# ARMv7M register map
Registers are read-write, no defined reset value unless marked. A register's access mark holds for its fields unless they carry their own. Offsets are from the block's base; [hi:lo] are bit positions; {n}, {i} and the like mark numbered series.

## DWT — Data Watchpoint and Trace
Base 0xE0001000
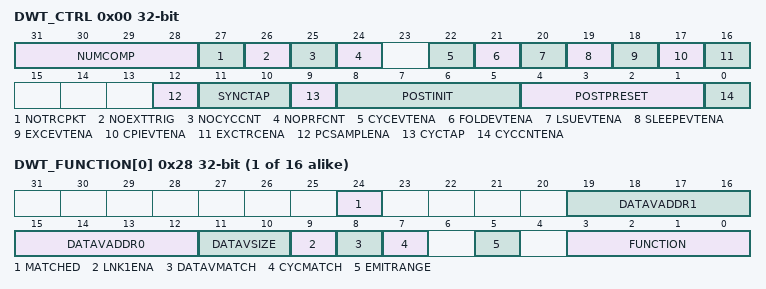
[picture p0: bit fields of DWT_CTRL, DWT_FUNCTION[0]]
0x00 DWT_CTRL — Data Watchpoint Trace Control Register provides configuration and status information and control of the unit
  [31:28] NUMCOMP — Number of comparators implemented
  [27] NOTRCPKT — Shows whether the implementation supports trace sampling and exception tracing
    0=Trace sampling and exception tracing supported; 1=Trace sampling and exception tracing not supported
  [26] NOEXTTRIG — Shows whether the implementation includes external match signals, CMPMATCH[N]
    0=CMPMATCH[N] supported; 1=CMPMATCH[N] not supported
  [25] NOCYCCNT — Shows whether the implementation supports a cycle counter
    0=Cycle counter supported; 1=Cycle counter not supported
  [24] NOPRFCNT — Shows whether the implementation supports the profiling counters
    0=Supported; 1=Not supported
  [22] CYCEVTENA — Enables POSTCNT underflow Event counter packets generation
    0=No POSTCNT underflow packets generated; 1=POSTCNT underflow packets generated, if PCSAMPLENA set to 0
  [21] FOLDEVTENA — Enables generation of the Folded-instruction counter overflow event
    0=Disabled; 1=Enabled
  [20] LSUEVTENA — Enables generation of the LSU counter overflow event
    0=Disabled; 1=Enabled
  [19] SLEEPEVTENA — Enables generation of the Sleep counter overflow event
    0=Disabled; 1=Enabled
  [18] EXCEVTENA — Enables generation of the Exception overhead counter overflow event
    0=Disabled; 1=Enabled
  [17] CPIEVTENA — Enables generation of the CPI counter overflow event
    0=Disabled; 1=Enabled
  [16] EXCTRCENA — Enables generation of exception trace
    0=Disabled; 1=Enabled
  [12] PCSAMPLENA — Enables use of POSTCNT counter as a timer for Periodic PC sample packet generation
    0=No Periodic PC sample packets generated; 1=Periodic PC sample packets generated
  [11:10] SYNCTAP — Selects the position of the synchronization packet counter tap on the CYCCNT counter
    0=Disabled. No Synchronization packets; 2=Synchronization counter tap at CYCCNT[26]; 3=Synchronization counter tap at CYCCNT[28]
  [9] CYCTAP — Selects the position of the POSTCNT tap on the CYCCNT counter
    0=POSTCNT tap at CYCCNT[6]; 1=POSTCNT tap at CYCCNT[10]
  [8:5] POSTINIT — Initial value for the POSTCNT counter
  [4:1] POSTPRESET — Reload value for the POSTCNT counter
  [0] CYCCNTENA — Enables CYCCNT
    0=Disabled; 1=Enabled
0x04 DWT_CYCCNT — Cycle Count register shows or sets the value of the processor cycle counter, CYCCNT
  [31:0] CYCCNT — Incrementing cycle counter value
0x08 DWT_CPICNT — CPI Count register counts additional cycles required to execute multi-cycle instructions and instruction fetch stalls
  [7:0] CPICNT — Base instruction overhead counter
0x0C DWT_EXCCNT — Exception Overhead Count register counts the total cycles spent in exception processing
  [7:0] EXCCNT — The exception overhead counter
0x10 DWT_SLEEPCNT — Sleep Count register counts the total number of cycles that the processor is sleeping
  [7:0] SLEEPCNT — Sleep counter
0x14 DWT_LSUCNT — LSU Count register increments on the additional cycles required to execute all load or store instructions
  [7:0] LSUCNT — Load-store overhead counter
0x18 DWT_FOLDCNT — Folded-instruction Count register increments on each instruction that takes 0 cycles
  [7:0] FOLDCNT — Folded instruction counter
0x1C DWT_PCSR ro — Program Counter Sample Register samples the current value of the program counter
  [31:0] EIASAMPLE — Executed Instruction Address sample value
{0x20+0x10*i} DWT_COMP[{i}] (i=0..15) — Comparator register provides a reference value for use by watchpoint comparator n
  [31:0] COMP — Reference value for comparison
{0x24+0x10*i} DWT_MASK[{i}] (i=0..15) — Comparator Mask register provides the size of the ignore mask applied to the access address for address range matching by comparator n
  [4:0] MASK — The size of the ignore mask, 0-31 bits, applied to address range matching
{0x28+0x10*i} DWT_FUNCTION[{i}] (i=0..15) — Data Watchpoint Trace Comparator Function Register
  [24] MATCHED — Comparator match
    0=No match; 1=Match
  [19:16] DATAVADDR1 — When the DATAVMATCH and LNK1ENA bits are both 1, this field can hold the comparator number of a second comparator to use for linked address comparison
  [15:12] DATAVADDR0 — When the DATAVMATCH bit is set to 1 this field can hold the comparator number of a comparator to use for linked address comparison
  [11:10] DATAVSIZE — For data value matching, specifies the size of the required data comparison
    0=Byte; 1=Halfword; 2=Word
  [9] LNK1ENA — Indicates whether the implementation supports use of a second linked comparator
    0=Second linked comparator not supported; 1=Second linked comparator supported
  [8] DATAVMATCH — Enables data value comparison, if supported
    0=Perform address comparison; 1=Perform data value comparison
  [7] CYCMATCH — DWT_FUNCTION0 only
    0=No comparison is performed; 1=Compare DWT_COMP0 with the cycle counter, DWT_CYCCNT
  [5] EMITRANGE — If the implementation supports trace sampling, enables generation of Data trace address packets, that hold Daddr[15
    0=Data trace address packets disabled; 1=Enable Data trace address packet generation
  [3:0] FUNCTION — Selects action taken on comparator match
    0== Disabled or LinkAddr()
